# STM32F105xx register map
File version: 1.2
Registers are 32-bit, read-write, reset 0x0 unless marked. A register's access mark holds for its fields unless they carry their own. Offsets are from the block's base; [hi:lo] are bit positions; {n}, {i} and the like mark numbered series; 'fields as' and 'values as' point back to an identical list.

## CAN2 — Controller area network
Base 0x40006800
Same registers: CAN1 0x40006400
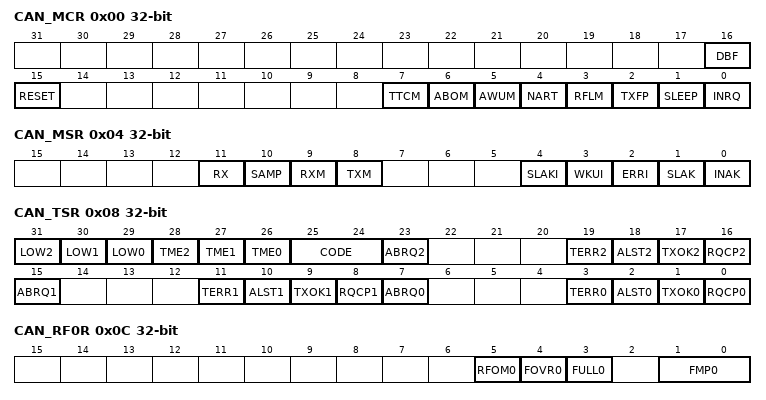
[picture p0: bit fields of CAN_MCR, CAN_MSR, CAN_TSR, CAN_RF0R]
0x00 CAN_MCR
  [16] DBF, [15] RESET, [7] TTCM, [6] ABOM, [5] AWUM, [4] NART, [3] RFLM, [2] TXFP, [1] SLEEP, [0] INRQ
0x04 CAN_MSR access per field
  [11] RX ro, [10] SAMP ro, [9] RXM ro, [8] TXM ro, [4] SLAKI rw, [3] WKUI rw, [2] ERRI rw, [1] SLAK ro, [0] INAK ro
0x08 CAN_TSR access per field
  [31] LOW2 ro — Lowest priority flag for mailbox 2
  [30] LOW1 ro — Lowest priority flag for mailbox 1
  [29] LOW0 ro — Lowest priority flag for mailbox 0
  [28] TME2 ro — Lowest priority flag for mailbox 2
  [27] TME1 ro — Lowest priority flag for mailbox 1
  [26] TME0 ro — Lowest priority flag for mailbox 0
  [25:24] CODE ro
  [23] ABRQ2 rw
  [19] TERR2 rw
  [18] ALST2 rw
  [17] TXOK2 rw
  [16] RQCP2 rw
  [15] ABRQ1 rw
  [11] TERR1 rw
  [10] ALST1 rw
  [9] TXOK1 rw
  [8] RQCP1 rw
  [7] ABRQ0 rw
  [3] TERR0 rw
  [2] ALST0 rw
  [1] TXOK0 rw
  [0] RQCP0 rw
0x0C CAN_RF0R access per field
  [5] RFOM0 rw, [4] FOVR0 rw, [3] FULL0 rw, [1:0] FMP0 ro
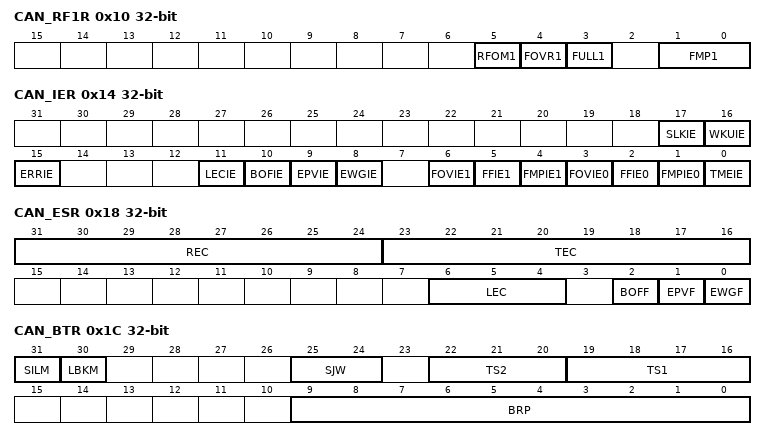
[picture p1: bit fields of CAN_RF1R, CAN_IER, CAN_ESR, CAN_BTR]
0x10 CAN_RF1R access per field
  [5] RFOM1 rw, [4] FOVR1 rw, [3] FULL1 rw, [1:0] FMP1 ro
0x14 CAN_IER
  [17] SLKIE, [16] WKUIE, [15] ERRIE, [11] LECIE, [10] BOFIE, [9] EPVIE, [8] EWGIE, [6] FOVIE1, [5] FFIE1, [4] FMPIE1, [3] FOVIE0, [2] FFIE0, [1] FMPIE0, [0] TMEIE
0x18 CAN_ESR access per field
  [31:24] REC ro, [23:16] TEC ro, [6:4] LEC rw, [2] BOFF ro, [1] EPVF ro, [0] EWGF ro
0x1C CAN_BTR
  [31] SILM, [30] LBKM, [25:24] SJW, [22:20] TS2, [19:16] TS1, [9:0] BRP
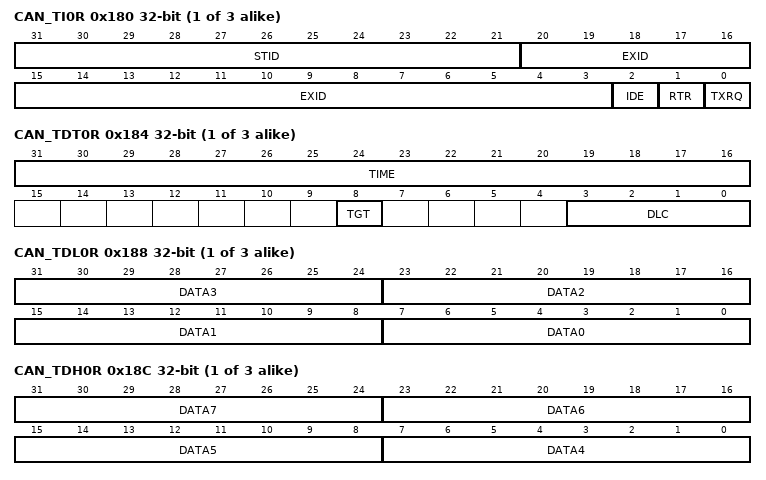
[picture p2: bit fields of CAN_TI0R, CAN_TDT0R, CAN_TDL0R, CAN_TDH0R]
{0x180+0x10*i} CAN_TI{i}R (i=0..2)
  [31:21] STID, [20:3] EXID, [2] IDE, [1] RTR, [0] TXRQ
{0x184+0x10*i} CAN_TDT{i}R (i=0..2)
  [31:16] TIME, [8] TGT, [3:0] DLC
{0x188+0x10*i} CAN_TDL{i}R (i=0..2)
  [8n+7:8n] DATA{n} (n=0..3)
{0x18C+0x10*i} CAN_TDH{i}R (i=0..2)
  [8n-25:8n-32] DATA{n} (n=4..7)
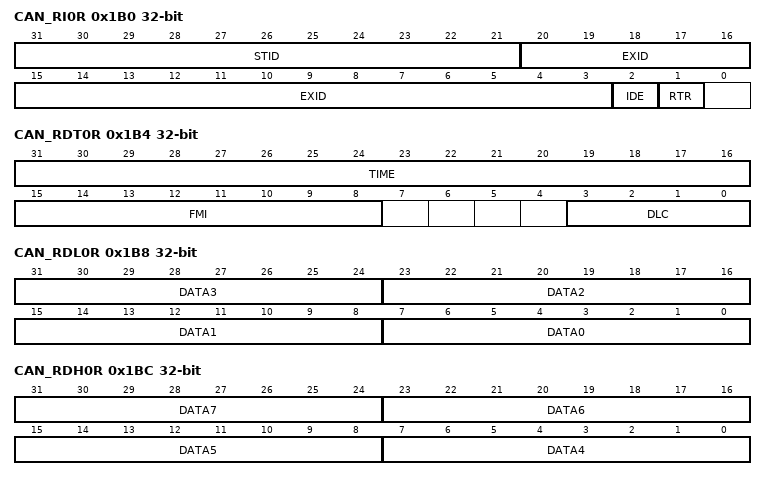
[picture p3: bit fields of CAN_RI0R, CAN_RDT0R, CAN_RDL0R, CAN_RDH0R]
0x1B0 CAN_RI0R ro
  [31:21] STID, [20:3] EXID, [2] IDE, [1] RTR
0x1B4 CAN_RDT0R ro
  [31:16] TIME, [15:8] FMI, [3:0] DLC
0x1B8 CAN_RDL0R ro
  [8n+7:8n] DATA{n} (n=0..3)
0x1BC CAN_RDH0R ro
  [8n-25:8n-32] DATA{n} (n=4..7)
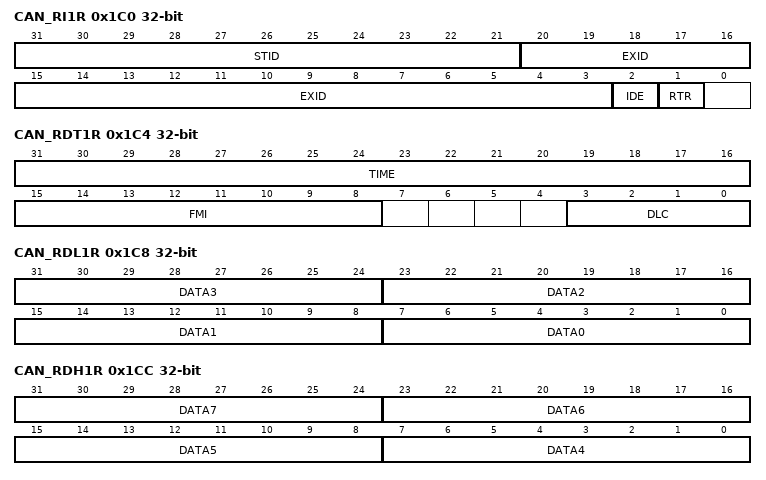
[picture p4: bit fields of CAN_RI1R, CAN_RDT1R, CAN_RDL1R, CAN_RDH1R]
0x1C0 CAN_RI1R ro
  [31:21] STID, [20:3] EXID, [2] IDE, [1] RTR
0x1C4 CAN_RDT1R ro
  [31:16] TIME, [15:8] FMI, [3:0] DLC
0x1C8 CAN_RDL1R ro
  [8n+7:8n] DATA{n} (n=0..3)
0x1CC CAN_RDH1R ro
  [8n-25:8n-32] DATA{n} (n=4..7)
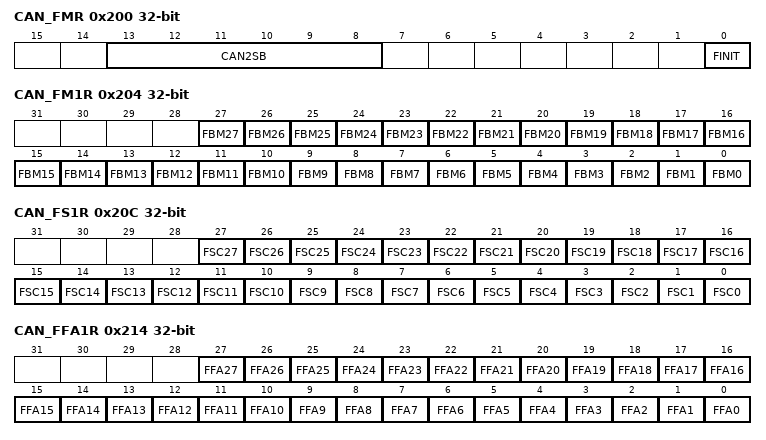
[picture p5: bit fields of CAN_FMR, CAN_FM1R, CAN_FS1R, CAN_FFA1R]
0x200 CAN_FMR
  [13:8] CAN2SB, [0] FINIT
0x204 CAN_FM1R
  [n] FBM{n} (n=0..27) — Filter mode
0x20C CAN_FS1R
  [n] FSC{n} (n=0..27) — Filter scale configuration
0x214 CAN_FFA1R
  [n] FFA{n} (n=0..27) — Filter FIFO assignment for filter {n}
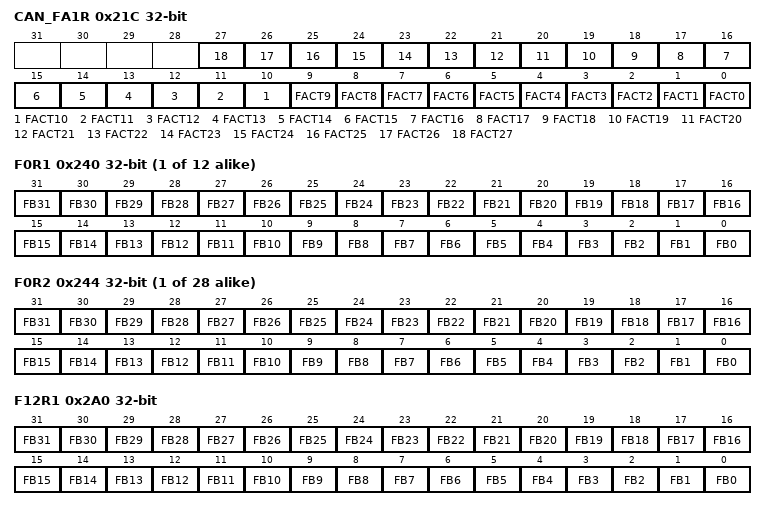
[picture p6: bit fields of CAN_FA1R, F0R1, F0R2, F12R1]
0x21C CAN_FA1R
  [n] FACT{n} (n=0..27) — Filter active
{0x240+8i} F{i}R1 (i=0..11) — Filter bank {i} register 1
  [n] FB{n} (n=0..31) — Filter bits
{0x244+8i} F{i}R2 (i=0..27) — Filter bank {i} register 2
  [n] FB{n} (n=0..31) — Filter bits
0x2A0 F12R1 — Filter bank 4 register 1
  [n] FB{n} (n=0..31) — Filter bits
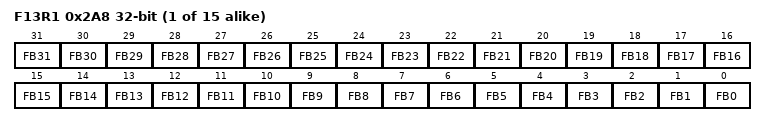
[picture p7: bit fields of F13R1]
{0x240+8i} F{i}R1 (i=13..27) — Filter bank {i} register 1
  [n] FB{n} (n=0..31) — Filter bits

## USB_OTG_HOST — USB on the go full speed
Base 0x50000400
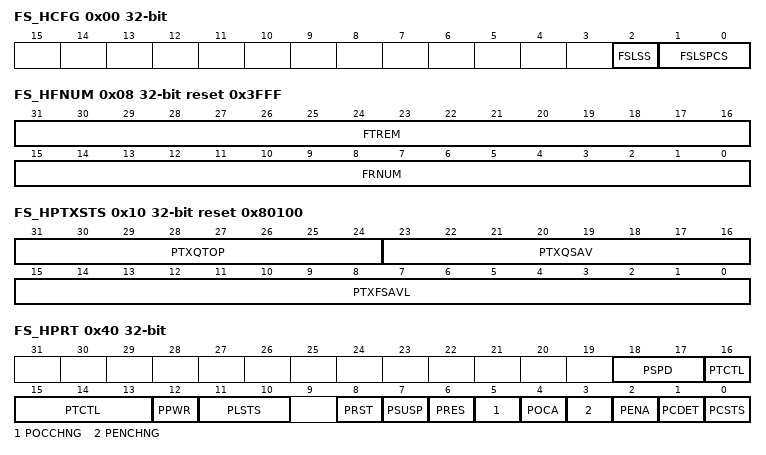
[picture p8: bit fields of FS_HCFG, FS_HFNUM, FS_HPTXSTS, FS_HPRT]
0x00 FS_HCFG access per field — OTG_FS host configuration register (OTG_FS_HCFG)
  [2] FSLSS ro — FS- and LS-only support
  [1:0] FSLSPCS rw — FS/LS PHY clock select
0x04 HFIR reset 0xEA60 — OTG_FS Host frame interval register
  [15:0] FRIVL — Frame interval
0x08 FS_HFNUM ro reset 0x3FFF — OTG_FS host frame number/frame time remaining register (OTG_FS_HFNUM)
  [31:16] FTREM — Frame time remaining
  [15:0] FRNUM — Frame number
0x10 FS_HPTXSTS access per field reset 0x80100 — OTG_FS_Host periodic transmit FIFO/queue status register (OTG_FS_HPTXSTS)
  [31:24] PTXQTOP ro — Top of the periodic transmit request queue
  [23:16] PTXQSAV ro — Periodic transmit request queue space available
  [15:0] PTXFSAVL rw — Periodic transmit data FIFO space available
0x14 HAINT ro — OTG_FS Host all channels interrupt register
  [15:0] HAINT — Channel interrupts
0x18 HAINTMSK — OTG_FS host all channels interrupt mask register
  [15:0] HAINTM — Channel interrupt mask
0x40 FS_HPRT access per field — OTG_FS host port control and status register (OTG_FS_HPRT)
  [18:17] PSPD ro — Port speed
  [16:13] PTCTL rw — Port test control
  [12] PPWR rw — Port power
  [11:10] PLSTS ro — Port line status
  [8] PRST rw — Port reset
  [7] PSUSP rw — Port suspend
  [6] PRES rw — Port resume
  [5] POCCHNG rw — Port overcurrent change
  [4] POCA ro — Port overcurrent active
  [3] PENCHNG rw — Port enable/disable change
  [2] PENA rw — Port enable
  [1] PCDET rw — Port connect detected
  [0] PCSTS ro — Port connect status
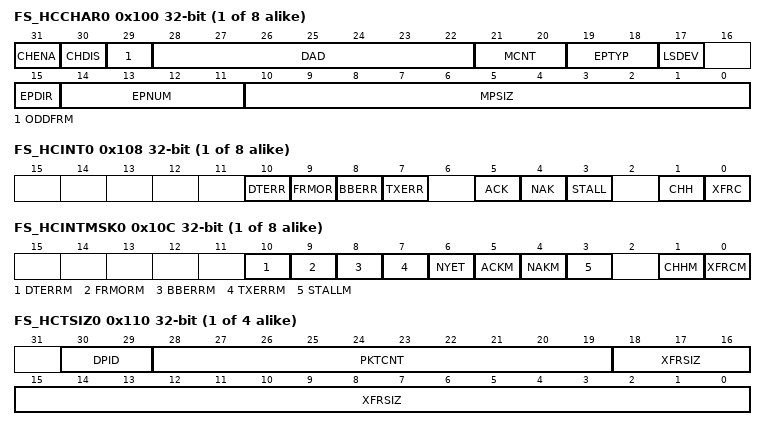
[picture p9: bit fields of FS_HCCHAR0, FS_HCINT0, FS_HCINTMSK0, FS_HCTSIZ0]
{0x100+0x20*i} FS_HCCHAR{i} (i=0..7) — OTG_FS host channel-{i} characteristics register (OTG_FS_HCCHAR{i})
  [31] CHENA — Channel enable
  [30] CHDIS — Channel disable
  [29] ODDFRM — Odd frame
  [28:22] DAD — Device address
  [21:20] MCNT — Multicount
  [19:18] EPTYP — Endpoint type
  [17] LSDEV — Low-speed device
  [15] EPDIR — Endpoint direction
  [14:11] EPNUM — Endpoint number
  [10:0] MPSIZ — Maximum packet size
{0x108+0x20*i} FS_HCINT{i} (i=0..7) — OTG_FS host channel-{i} interrupt register (OTG_FS_HCINT{i})
  [10] DTERR — Data toggle error
  [9] FRMOR — Frame overrun
  [8] BBERR — Babble error
  [7] TXERR — Transaction error
  [5] ACK — ACK response received/transmitted interrupt
  [4] NAK — NAK response received interrupt
  [3] STALL — STALL response received interrupt
  [1] CHH — Channel halted
  [0] XFRC — Transfer completed
{0x10C+0x20*i} FS_HCINTMSK{i} (i=0..7) — OTG_FS host channel-{i} mask register (OTG_FS_HCINTMSK{i})
  [10] DTERRM — Data toggle error mask
  [9] FRMORM — Frame overrun mask
  [8] BBERRM — Babble error mask
  [7] TXERRM — Transaction error mask
  [6] NYET — response received interrupt mask
  [5] ACKM — ACK response received/transmitted interrupt mask
  [4] NAKM — NAK response received interrupt mask
  [3] STALLM — STALL response received interrupt mask
  [1] CHHM — Channel halted mask
  [0] XFRCM — Transfer completed mask
{0x110+0x20*i} FS_HCTSIZ{i} (i=0..3) — OTG_FS host channel-{i} transfer size register
  [30:29] DPID — Data PID
  [28:19] PKTCNT — Packet count
  [18:0] XFRSIZ — Transfer size
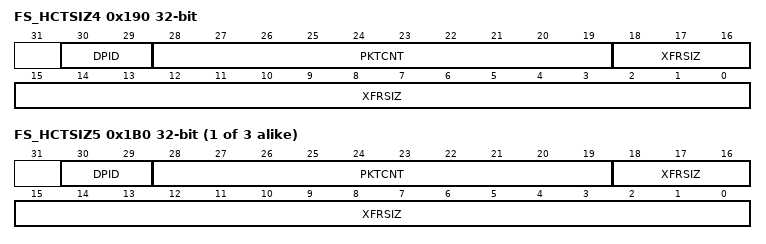
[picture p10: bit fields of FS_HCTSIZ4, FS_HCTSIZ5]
0x190 FS_HCTSIZ4 — OTG_FS host channel-x transfer size register
  fields as FS_HCTSIZ0
{0x110+0x20*i} FS_HCTSIZ{i} (i=5..7) — OTG_FS host channel-{i} transfer size register
  fields as FS_HCTSIZ0
